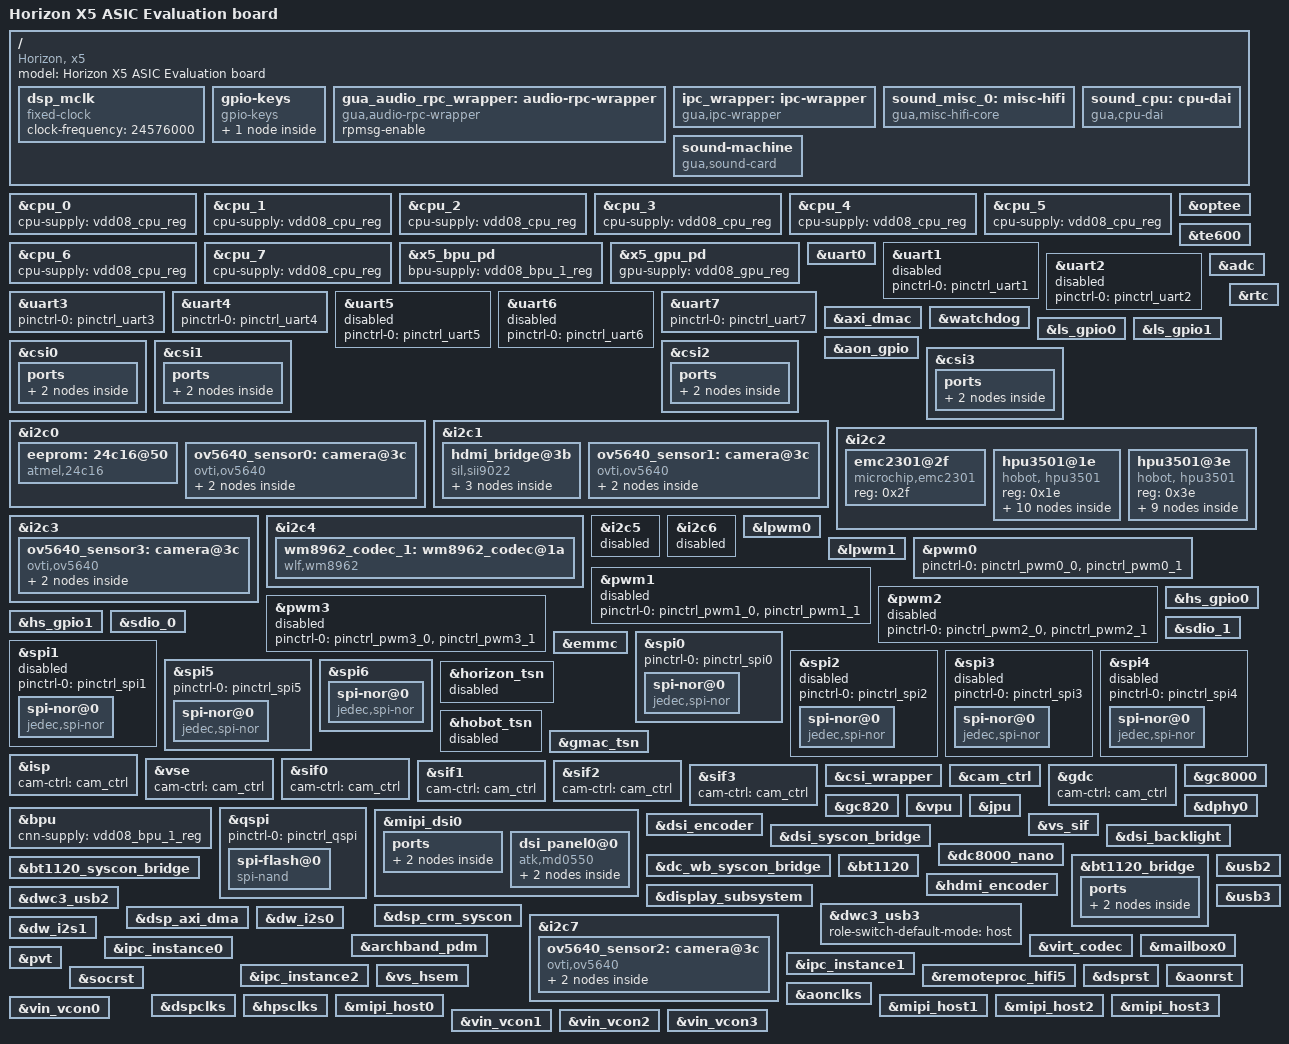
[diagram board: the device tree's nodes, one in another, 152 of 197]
// SPDX-License-Identifier: GPL-2.0
/*
 * dts for x5 asic evb platform
 *
 * Copyright (C) 2020 Verisilicon Inc.
 *
 */

/dts-v1/;
#include "x5.dtsi"
#include "x5-memory.dtsi"
#include "pinmux-func.dtsi"
#include "pinmux-gpio.dtsi"
#include <dt-bindings/input/linux-event-codes.h>

/ {
	model = "Horizon X5 ASIC Evaluation board";
	compatible = "Horizon, x5";

	#address-cells = <2>;
	#size-cells = <2>;

	dsp_mclk: dsp_mclk {
		compatible = "fixed-clock";
		#clock-cells = <0>;
		clock-frequency = <24576000>;
	};

	gpio-keys {
		compatible = "gpio-keys";
		autorepeat;
		pinctrl-names = "default";
		pinctrl-0 = <&aon_gpio_3>;

		key-power {
			debounce-interval = <100>;
			gpios = <&aon_gpio_porta 3 GPIO_ACTIVE_LOW>;
			label = "GPIO Key Power";
			linux,code = <KEY_WAKEUP>;
			wakeup-source;
		};
	};

	gua_audio_rpc_wrapper:audio-rpc-wrapper {
		compatible = "gua,audio-rpc-wrapper";
		rpmsg-enable;
		status = "okay";
	};

	ipc_wrapper:ipc-wrapper {
		compatible = "gua,ipc-wrapper";
		rpmsg-enable;
		status = "okay";
		gua-ipc = <&ipc_instance0>;
	};

	sound_misc_0:misc-hifi {
		compatible = "gua,misc-hifi-core";
		// core channel
		control-rpmsg-channel-mapping = <0x00 0x00      // a core to hifi 0
								>;
		msg-wrapper = <&ipc_wrapper>;
		gua-ipc = <&ipc_instance0>;
		status = "okay";
	};

	sound_cpu:cpu-dai {
		compatible = "gua,cpu-dai";
		msg-wrapper = <&ipc_wrapper>;
		gua,pcm-buffer-size = <0x1E000>;
		pcm-rpmsg-channel-mapping = <0x00>, <0x00>, <0x00>, <0x00>, <0x00>, <0x00>;
		status = "okay";
	};

	sound-machine {
		compatible = "gua,sound-card";
		model = "gua-audio";
		cpu-dai = <&sound_cpu>;
		status = "okay";
	};
};

&cpu_0 {
	cpu-supply = <&vdd08_cpu_reg>;
};

&cpu_1 {
	cpu-supply = <&vdd08_cpu_reg>;
};

&cpu_2 {
	cpu-supply = <&vdd08_cpu_reg>;
};

&cpu_3 {
	cpu-supply = <&vdd08_cpu_reg>;
};

&cpu_4 {
	cpu-supply = <&vdd08_cpu_reg>;
};

&cpu_5 {
	cpu-supply = <&vdd08_cpu_reg>;
};

&cpu_6 {
	cpu-supply = <&vdd08_cpu_reg>;
};

&cpu_7 {
	cpu-supply = <&vdd08_cpu_reg>;
};

&x5_bpu_pd {
	bpu-supply = <&vdd08_bpu_1_reg>;
};

&x5_gpu_pd {
	gpu-supply = <&vdd08_gpu_reg>;
};

&optee {
	status = "okay";
};

&te600 {
	status = "okay";
};

&uart0 {
	status = "okay";
};

&uart1 {
	status = "disabled";
	pinctrl-names = "default";
	pinctrl-0 = <&pinctrl_uart1>;
};

&uart2 {
	status = "disabled";
	pinctrl-names = "default";
	pinctrl-0 = <&pinctrl_uart2>;
};

&uart3 {
	status = "okay";
	pinctrl-names = "default";
	pinctrl-0 = <&pinctrl_uart3>;
};

&uart4 {
	status = "okay";
	pinctrl-names = "default";
	pinctrl-0 = <&pinctrl_uart4>;
};

&uart5 {
	status = "disabled";
	pinctrl-names = "default";
	pinctrl-0 = <&pinctrl_uart5>;
};

&uart6 {
	status = "disabled";
	pinctrl-names = "default";
	pinctrl-0 = <&pinctrl_uart6>;
};

&uart7 {
	status = "okay";
	pinctrl-names = "default";
	pinctrl-0 = <&pinctrl_uart7>;
};

&adc {
	status = "okay";
};

&axi_dmac {
	status = "okay";
};

&watchdog {
	status = "okay";
};

&ls_gpio0 {
	status = "okay";
};

&ls_gpio1 {
	status = "okay";
};

&aon_gpio {
	status = "okay";
};

&rtc {
	status = "okay";
};

&csi0 {
	status = "okay";

	ports {
		port@0 {
			x5_mipi_csi0_from_ov5640: endpoint {
				remote-endpoint = <&ov5640_to_mipi_csi0>;
				clock-lanes = <0>;
				data-lanes = <1 2>;
				lane-rate = <400>;
				vc_id = <0>;
			};
		};
	};
};

&csi1 {
	status = "okay";

	ports {
		port@0 {
			x5_mipi_csi1_from_ov5640: endpoint {
				remote-endpoint = <&ov5640_to_mipi_csi1>;
				clock-lanes = <0>;
				data-lanes = <1 2>;
				lane-rate = <400>;
				vc_id = <0>;
			};
		};
	};
};

&csi2 {
	status = "okay";

	ports {
		port@0 {
			x5_mipi_csi2_from_ov5640: endpoint {
				remote-endpoint = <&ov5640_to_mipi_csi2>;
				clock-lanes = <0>;
				data-lanes = <1 2>;
				lane-rate = <400>;
				vc_id = <0>;
			};
		};
	};
};

&csi3 {
	status = "okay";

	ports {
		port@0 {
			x5_mipi_csi3_from_ov5640: endpoint {
				remote-endpoint = <&ov5640_to_mipi_csi3>;
				clock-lanes = <0>;
				data-lanes = <1 2>;
				lane-rate = <400>;
				vc_id = <0>;
			};
		};
	};
};

&i2c0 {
	status = "okay";

	eeprom: 24c16@50 {
		compatible = "atmel,24c16";
		reg = <0x50>;
		address-width = <16>;
		pagesize = <16>;
	};

	ov5640_sensor0: camera@3c {
		compatible = "ovti,ov5640";
		pinctrl-names = "default";
		pinctrl-0 = <&pinctrl_sensor2_mclk &aon_gpio_0 &aon_gpio_1>;
		powerdown-gpios = <&aon_gpio_porta 0 GPIO_ACTIVE_HIGH>;
		reset-gpios = <&aon_gpio_porta 1 GPIO_ACTIVE_LOW>;
		reg = <0x3c>;
		clocks = <&hpsclks X5_LSIO_SENSOR2_CLK>;
		clock-names = "xclk";
		rotation = <0>;

		port {
			/* MIPI CSI-2 bus endpoint */
			ov5640_to_mipi_csi0: endpoint {
				remote-endpoint = <&x5_mipi_csi0_from_ov5640>;
				clock-lanes = <0>;
				data-lanes = <1 2>;
			};
		};
	};

};

&i2c1 {
	status = "okay";

	hdmi_bridge@3b {
		compatible = "sil,sii9022";
		reg = <0x3b>;

		pinctrl-names = "default";
		pinctrl-0 = <&lsio_gpio0_30>;

		reset-gpios = <&ls_gpio0_porta 30 GPIO_ACTIVE_LOW>;

		status = "okay";

		ports {
			#address-cells = <1>;
			#size-cells = <0>;

			port@0 {
				reg = <0>;
				hdmi_bridge_in: endpoint {
					remote-endpoint =
						<&bt1120_bridge_out>;
				};
			};
		};
	};

	ov5640_sensor1: camera@3c {
		compatible = "ovti,ov5640";
 		pinctrl-names = "default";
		pinctrl-0 = <&pinctrl_sensor3_mclk &aon_gpio_2 &aon_gpio_5>;
		powerdown-gpios = <&aon_gpio_porta 2 GPIO_ACTIVE_HIGH>;
		reset-gpios = <&aon_gpio_porta 5 GPIO_ACTIVE_LOW>;
		reg = <0x3c>;
		clocks = <&hpsclks X5_LSIO_SENSOR3_CLK>;
		clock-names = "xclk";
		rotation = <0>;
		port {
			/* MIPI CSI-2 bus endpoint */
			ov5640_to_mipi_csi1: endpoint {
				remote-endpoint = <&x5_mipi_csi1_from_ov5640>;
				clock-lanes = <0>;
				data-lanes = <1 2>;
 			};
 		};
 	};

};

&i2c2 {
	status = "okay";

	emc2301@2f {
		compatible = "microchip,emc2301";
		reg = <0x2f>;
		status = "okay";
	};

	/* master pmic */
	hpu3501@1e {
		reg = <0x1e>;
		compatible = "hobot, hpu3501";

		hpu3501-regulator {

			master;
			fault_cfgr = <0x7f>;

			regulators {

				vdd08_ddr_reg: BUCK1 {
					regulator-name = "VDD08_DDR";
					regulator-min-microvolt = <800000>;
					regulator-max-microvolt = <800000>;
					regulator-ramp-delay = <3000>;
					regulator-always-on;
					regulator-boot-on;
				};

				vdd08_gpu_reg: BUCK2 {
					regulator-name = "VDD08_GPU";
					regulator-min-microvolt = <800000>;
					regulator-max-microvolt = <800000>;
					regulator-ramp-delay = <3000>;
					regulator-enable-ramp-delay = <3000>;
				};

				vdd08_soc_reg: BUCK3 {
					regulator-name = "VDD08_SOC";
					regulator-min-microvolt = <800000>;
					regulator-max-microvolt = <800000>;
					regulator-always-on;
					regulator-boot-on;
				};

				vdd08_dsp_reg: BUCK4 {
					regulator-name = "VDD08_DSP";
					regulator-min-microvolt = <800000>;
					regulator-max-microvolt = <800000>;
					regulator-always-on;
					regulator-boot-on;
				};

				vddi_ddr_1v8_reg: BUCK5 {
					regulator-name = "VDDI_DDR_1V8";
					regulator-min-microvolt = <1800000>;
					regulator-max-microvolt = <1800000>;
					regulator-always-on;
					regulator-boot-on;
				};

				vdd08_aon_reg: LDO1 {
					regulator-name = "VDD08_AON";
					regulator-min-microvolt = <800000>;
					regulator-max-microvolt = <800000>;
					regulator-always-on;
					regulator-boot-on;
				};

				vddio18_aon_reg: LDO2_CFG1 {
					regulator-name = "VDDIO18_AON";
					regulator-min-microvolt = <1800000>;
					regulator-max-microvolt = <1800000>;
					regulator-always-on;
					regulator-boot-on;
				};

				vddio18_dsp_reg: LDO3 {
					regulator-name = "VDDIO_DSP";
					regulator-min-microvolt = <1800000>;
					regulator-max-microvolt = <1800000>;
					regulator-always-on;
					regulator-boot-on;
				};
			};
		};
	};

	/* slave pmic */
	hpu3501@3e {
		reg = <0x3e>;
		compatible = "hobot, hpu3501";

		hpu3501-regulator {

			fault_cfgr = <0x7f>;

			regulators {
				#address-cells = <1>;
				#size-cells = <0>;

				vdd08_bpu_1_reg: BUCK1 {
					regulator-name = "VDD08_BPU_1";
					regulator-min-microvolt = <800000>;
					regulator-max-microvolt = <800000>;
					regulator-enable-ramp-delay = <3000>;
				};
				#if 0
				/*
					bpu buck 2 will be controlled by buck 1 with dual phase
				*/
				vdd08_bpu_2_reg: BUCK2 {
					regulator-name = "VDD08_BPU_2";
					regulator-min-microvolt = <800000>;
					regulator-max-microvolt = <800000>;
					regulator-ramp-delay = <3000>;
					regulator-enable-ramp-delay = <3000>;
				};
				#endif
				vdd08_cpu_reg: BUCK3 {
					regulator-name = "VDD08_CPU";
					regulator-min-microvolt = <800000>;
					regulator-max-microvolt = <1000000>;
					regulator-enable-ramp-delay = <3000>;
					regulator-always-on;
					regulator-boot-on;
				};

				vddq1v1_ddr_reg: BUCK4 {
					regulator-name = "VDDQ_DDR_1V1";
					regulator-min-microvolt = <1100000>;
					regulator-max-microvolt = <1100000>;
					regulator-always-on;
					regulator-boot-on;
				};

				vddio18_soc_reg: BUCK5 {
					regulator-name = "VDDIO18_SOC";
					regulator-min-microvolt = <1800000>;
					regulator-max-microvolt = <1800000>;
					regulator-ramp-delay = <3000>;
					regulator-always-on;
					regulator-boot-on;
				};

				avdd0v8_reg: LDO1 {
					regulator-name = "AVDD_0V8";
					regulator-min-microvolt = <800000>;
					regulator-max-microvolt = <800000>;
					regulator-ramp-delay = <3000>;
					regulator-always-on;
					regulator-boot-on;
				};

				usb_avdd_3v3_reg: LDO2_CFG1 {
					regulator-name = "USB_AVDD_3V3";
					regulator-min-microvolt = <3300000>;
					regulator-max-microvolt = <3300000>;
					regulator-ramp-delay = <3000>;
					regulator-always-on;
					regulator-boot-on;
				};

				avdd_1v8_reg: LDO3 {
					regulator-name = "AVDD_1V8";
					regulator-min-microvolt = <1800000>;
					regulator-max-microvolt = <1800000>;
					regulator-ramp-delay = <3000>;
					regulator-always-on;
					regulator-boot-on;
				};
			};
		};
	};
};

&i2c3 {
	status = "okay";

	ov5640_sensor3: camera@3c {
		compatible = "ovti,ov5640";
		pinctrl-names = "default";
		pinctrl-0 = <&pinctrl_sensor1_mclk &lsio_gpio0_22 &lsio_gpio0_23>;
		powerdown-gpios = <&ls_gpio0_porta 22 GPIO_ACTIVE_HIGH>;
		reset-gpios = <&ls_gpio0_porta 23 GPIO_ACTIVE_LOW>;
		reg = <0x3c>;
		clocks = <&hpsclks X5_LSIO_SENSOR1_CLK>;
		clock-names = "xclk";
		rotation = <0>;

		port {
			/* MIPI CSI-2 bus endpoint */
			ov5640_to_mipi_csi3: endpoint {
				remote-endpoint = <&x5_mipi_csi3_from_ov5640>;
				clock-lanes = <0>;
				data-lanes = <1 2>;
			};
		};
	};
};

&i2c4 {
	status = "okay";

	wm8962_codec_1: wm8962_codec@1a {
		compatible = "wlf,wm8962";
		reg = <0x1a>;
		channel = <2>;
		clocks = <&dsp_mclk>;
		#sound-dai-cells = <0>;
		status = "okay";
		gpio-cfg = <
			0x0000 /* 0:Default */
			0x0000 /* 1:Default */
			0x0013 /* 2:FN_DMICCLK */
			0x0000 /* 3:Default */
			0x8014 /* 4:FN_DMICCDAT */
			0x0000 /* 5:Default */
		>;
	};
};

&i2c5 {
	status = "disabled";
	//need add rising/falling time for i2c running at 400K
	i2c-scl-rising-time-ns = <20>;
	i2c-scl-falling-time-ns = <4>;
	clock-frequency = <400000>;
};

&i2c6 {
	status = "disabled";
};

&lpwm0 {
	status = "okay";
};

&lpwm1 {
	status = "okay";
};

&pwm0 {
	status = "okay";
	pinctrl-names = "default";
	pinctrl-0 = <&pinctrl_pwm0_0 &pinctrl_pwm0_1>;
};

&pwm1 {
	status = "disabled";
	pinctrl-names = "default";
	pinctrl-0 = <&pinctrl_pwm1_0 &pinctrl_pwm1_1>;
};

&pwm2 {
	status = "disabled";
	pinctrl-names = "default";
	pinctrl-0 = <&pinctrl_pwm2_0 &pinctrl_pwm2_1>;
};

&pwm3 {
	status = "disabled";
	pinctrl-names = "default";
	pinctrl-0 = <&pinctrl_pwm3_0 &pinctrl_pwm3_1>;
};

&hs_gpio0 {
	status = "okay";
};

&hs_gpio1 {
	status = "okay";
};

&sdio_0 {
	status = "okay";
	no-1-8-v;

	pinctrl-names = "default";
	pinctrl-0 = <&pinctrl_sd>;
	max-frequency = <50000000>;
};

&sdio_1 {
	status = "okay";
	max-frequency = <200000000>;
	pinctrl-names = "default";
	pinctrl-0 = <&pinctrl_sdio>;
};

&emmc {
	status = "okay";
	max-frequency = <200000000>;
	pinctrl-names = "default";
	pinctrl-0 = <&pinctrl_emmc>;
};

&spi0 {
	status = "okay";
	pinctrl-names = "default";
	pinctrl-0 = <&pinctrl_spi0>;

	spi-nor@0 {
		compatible = "jedec,spi-nor";
		spi-max-frequency = <50000000>;
		rx-sample-delay-ns = <12>;
		reg = <0>;
	};
};

&spi1 {
	status = "disabled";
	pinctrl-names = "default";
	pinctrl-0 = <&pinctrl_spi1>;

	spi-nor@0 {
		compatible = "jedec,spi-nor";
		spi-max-frequency = <50000000>;
		rx-sample-delay-ns = <12>;
		reg = <0>;
	};
};

&spi2 {
	status = "disabled";
	pinctrl-names = "default";
	pinctrl-0 = <&pinctrl_spi2>;

	spi-nor@0 {
		compatible = "jedec,spi-nor";
		spi-max-frequency = <50000000>;
		rx-sample-delay-ns = <12>;
		reg = <0>;
	};
};

&spi3 {
	status = "disabled";
	pinctrl-names = "default";
	pinctrl-0 = <&pinctrl_spi3>;

	spi-nor@0 {
		compatible = "jedec,spi-nor";
		spi-max-frequency = <50000000>;
		rx-sample-delay-ns = <12>;
		reg = <0>;
	};
};

&spi4 {
	status = "disabled";
	pinctrl-names = "default";
	pinctrl-0 = <&pinctrl_spi4>;

	spi-nor@0 {
		compatible = "jedec,spi-nor";
		spi-max-frequency = <50000000>;
		rx-sample-delay-ns = <12>;
		reg = <0>;
	};
};

&spi5 {
	status = "okay";
	pinctrl-names = "default";
	pinctrl-0 = <&pinctrl_spi5>;

	spi-nor@0 {
		compatible = "jedec,spi-nor";
		spi-max-frequency = <50000000>;
		rx-sample-delay-ns = <12>;
		reg = <0>;
	};
};

&spi6 {
	status = "okay";

	spi-nor@0 {
		compatible = "jedec,spi-nor";
		spi-max-frequency = <50000000>;
		reg = <0>;
		rx-sample-delay-ns = <12>;
	};
};

&horizon_tsn {
	status = "disabled";

	phy-mode = "rgmii-id";
	pinctrl-names = "default";
	pinctrl-0 = <&pinctrl_enet &lsio_gpio0_29>;
	phyreset-gpio = <&ls_gpio0_porta 29 GPIO_ACTIVE_HIGH>;
};

&hobot_tsn {
	status = "disabled";

	phy-mode = "rgmii-id";
	pinctrl-names = "default";
	pinctrl-0 = <&pinctrl_enet &lsio_gpio0_29>;
	phyreset-gpio = <&ls_gpio0_porta 29 GPIO_ACTIVE_HIGH>;
};

&gmac_tsn {
	status = "okay";

	phy-mode = "rgmii-id";
	pinctrl-names = "default";
	pinctrl-0 = <&pinctrl_enet &lsio_gpio0_29>;
	phyreset-gpio = <&ls_gpio0_porta 29 GPIO_ACTIVE_HIGH>;
};

&isp {
	cam-ctrl = <&cam_ctrl>;
	status = "okay";
};

&vse {
	cam-ctrl = <&cam_ctrl>;
	status = "okay";
};

&sif0 {
	cam-ctrl = <&cam_ctrl>;
	status = "okay";
};

&sif1 {
	cam-ctrl = <&cam_ctrl>;
	status = "okay";
};

&sif2 {
	cam-ctrl = <&cam_ctrl>;
	status = "okay";
};

&sif3 {
	cam-ctrl = <&cam_ctrl>;
	status = "okay";
};

&csi0 {
	csi-wrapper = <&csi_wrapper>;
	cam-ctrl = <&cam_ctrl>;
	status = "okay";
};

&csi1 {
	csi-wrapper = <&csi_wrapper>;
	cam-ctrl = <&cam_ctrl>;
	status = "okay";
};

&csi2 {
	csi-wrapper = <&csi_wrapper>;
	cam-ctrl = <&cam_ctrl>;
	status = "okay";
};

&csi3 {
	csi-wrapper = <&csi_wrapper>;
	cam-ctrl = <&cam_ctrl>;
	status = "okay";
};

&csi_wrapper {
	status = "okay";
};

&cam_ctrl {
	status = "okay";
};

&gdc {
	cam-ctrl = <&cam_ctrl>;
	status = "okay";
};

&gc8000 {
	status = "okay";
};

&gc820 {
	status = "okay";
};

&bpu {
	status = "okay";
};

&qspi {
	status = "okay";
	pinctrl-names = "default";
	pinctrl-0 = <&pinctrl_qspi>;

	spi-flash@0 {
		compatible = "spi-nand";
		spi-max-frequency = <100000000>;
		rx-sample-delay-ns = <10>;
		reg = <0>;
	};
};

&vpu {
	status = "okay";
};

&jpu {
	status = "okay";
};

&bpu {
	cnn-supply = <&vdd08_bpu_1_reg>;
};

&dphy0 {
	status = "okay";
};

&mipi_dsi0 {
	status = "okay";

	ports {
		port@1 {
			reg = <1>;
			mipi_dsi_out: endpoint {
				remote-endpoint = <&panel_in>;
			};
		};
	};

	dsi_panel0@0 {
		compatible = "atk,md0550";
		reg = <0>;

		pinctrl-names = "default";
		pinctrl-0 = <&lsio_gpio0_9>;
		reset-gpios = <&ls_gpio0_porta 9 GPIO_ACTIVE_HIGH>;
		backlight = <&dsi_backlight>;

		port {
			panel_in: endpoint {
				remote-endpoint =
					<&mipi_dsi_out>;
			};
		};
	};
};

&dsi_encoder {
	status = "okay";
};

&vs_sif {
	status = "okay";
	clock-names = "axi_clk", "apb_clk";
	clocks = <&hpsclks X5_DISP_SIF_ACLK>,
		<&hpsclks X5_DISP_SIF_PCLK>;
};

&dsi_syscon_bridge {
	status = "okay";
};

&dsi_backlight {
	status = "okay";
};

&dc_wb_syscon_bridge {
	status = "okay";
};

&dc8000_nano {
	status = "okay";


};

&bt1120_bridge {
	ports {
		port@1 {
			reg = <1>;
			bt1120_bridge_out: endpoint {
				remote-endpoint = <&hdmi_bridge_in>;
			};
		};
	};
};

&bt1120_syscon_bridge {
	status = "okay";
};

&bt1120 {
	status = "okay";
};

&hdmi_encoder {
	status = "okay";

};

&display_subsystem {
	status = "okay";
};

&dwc3_usb2 {
	status = "okay";
};

&usb2 {
	status = "okay";
};

&dwc3_usb3 {
	role-switch-default-mode = "host";

	status = "okay";
};

&usb3 {
	status = "okay";
};

&dsp_crm_syscon {
	status = "okay";
};

&i2c7 {
	status = "okay";

	ov5640_sensor2: camera@3c {
		compatible = "ovti,ov5640";
		pinctrl-names = "default";
		pinctrl-0 = <&pinctrl_sensor0_mclk &aon_gpio_7 &aon_gpio_6>;
		powerdown-gpios = <&aon_gpio_porta 7 GPIO_ACTIVE_HIGH>;
		reset-gpios = <&aon_gpio_porta 6 GPIO_ACTIVE_LOW>;
		reg = <0x3c>;
		clocks = <&hpsclks X5_LSIO_SENSOR0_CLK>;
		clock-names = "xclk";
		rotation = <0>;

		port {
			/* MIPI CSI-2 bus endpoint */
			ov5640_to_mipi_csi2: endpoint {
				remote-endpoint = <&x5_mipi_csi2_from_ov5640>;
				clock-lanes = <0>;
				data-lanes = <1 2>;
			};
		};
	};
};

&dsp_axi_dma {
	status = "okay";
};

&dw_i2s0 {
	status = "okay";
};

&dw_i2s1 {
	status = "okay";
};

&archband_pdm {
	status = "okay";
};

&virt_codec {
	status = "okay";
};

&mailbox0 {
	status = "okay";
};

&ipc_instance0 {
	status = "okay";
	local-offset = <0x0>;
	remote-offset = <0x400>;
};

&ipc_instance1 {
	status = "okay";
	local-offset = <0x800>;
	remote-offset = <0xc00>;
};

&ipc_instance2 {
	status = "okay";
	local-offset = <0x1000>;
	remote-offset = <0x4000>;
};

&remoteproc_hifi5 {
	status = "okay";
	hifi5-rpmsg-channel-mapping = <0x00>, <0x00>;
	msg-wrapper = <&ipc_wrapper>;
	remoteproc-ipc = <&ipc_instance1>;
};

/* &hifi5_loader {
	status = "okay";
}; */

&vs_hsem {
	status = "okay";
};

/* &dsp_mailbox {
	status = "okay";
}; */

&pvt {
	status = "okay";
};

&dsprst {
	status = "okay";
};

&aonrst {
	status = "okay";
};

&socrst {
	status = "okay";
};

&aonclks {
	status = "okay";
};

&dspclks {
	status = "okay";
};

&hpsclks {
	status = "okay";
};

&mipi_host0 {
	status = "okay";
	pinctrl-names = "enable", "disable";
	pinctrl-0 = <&pinctrl_sensor2_mclk>;	//mclk2
	pinctrl-1 = <&lsio_gpio0_26>;
	snrclk-idx = <2>;  //mclk index
};

&mipi_host1 {
	status = "okay";
	pinctrl-names = "enable", "disable";
	pinctrl-0 = <&pinctrl_sensor3_mclk>;	//mclk3
	pinctrl-1 = <&lsio_gpio0_27>;
	snrclk-idx = <3>;  //mclk index
};

&mipi_host2 {
	status = "okay";
	pinctrl-names = "enable", "disable";
	pinctrl-0 = <&pinctrl_sensor0_mclk>;	//mclk0
	pinctrl-1 = <&lsio_gpio0_24>;
	snrclk-idx = <0>;  //mclk index
};

&mipi_host3 {
	status = "okay";
	pinctrl-names = "enable", "disable";
	pinctrl-0 = <&pinctrl_sensor1_mclk>;	//mclk1
	pinctrl-1 = <&lsio_gpio0_25>;
	snrclk-idx = <1>;  //mclk index
};

&vin_vcon0 {
	status = "okay";
	/* camera sensor
	   reset gpio:	   AON_GPIO_PIN1:	  499
	   pwd gpio:	   AON_GPIO_PIN0:	  498
	*/
	pinctrl-names = "default";
	pinctrl-0 = <&aon_gpio_0 &aon_gpio_1>;
	gpio_oth = <498 499>;	//pwd gpio、reset gpio
	bus = <0>;	//i2c-0
	lpwm_chn = <0 1 2 3>;
};

&vin_vcon1 {
	status = "okay";
	/* camera sensor
	   reset gpio:	   AON_GPIO_PIN5:	  503
	   pwd gpio:	   AON_GPIO_PIN2:	  500
	*/
	pinctrl-names = "default";
	pinctrl-0 = <&aon_gpio_2 &aon_gpio_5>;
	gpio_oth = <500 503>;	//pwd gpio、reset gpio
	bus = <1>;	//i2c-1
	lpwm_chn = <0 1 2 3>;
};

&vin_vcon2 {
	status = "okay";
	/* camera sensor
	   reset gpio:	   AON_GPIO_PIN6:	  504
	   pwd gpio:	   AON_GPIO_PIN7:	  505
	*/
	pinctrl-names = "default";
	pinctrl-0 = <&aon_gpio_7 &aon_gpio_6>;
	gpio_oth = <505 504>;	//pwd gpio、reset gpio
	bus = <7>;	//NOTICE i2c-7 same this hifi5
	lpwm_chn = <0 1 2 3>;
};

&vin_vcon3 {
	status = "okay";
	/* camera sensor
	   reset gpio:	   LSIO_GPIO0_23:	  402
	   pwd gpio:	   LSIO_GPIO0_22:	  401
	*/
	pinctrl-names = "default";
	pinctrl-0 = <&lsio_gpio0_22 &lsio_gpio0_23>;
	gpio_oth = <401 402>;	//pwd gpio、reset gpio
	bus = <3>;	//i2c-3
	lpwm_chn = <0 1 2 3>;
};
